# solox_a9 register map
File version: 1.0
Default CMSIS device
Registers are 32-bit, read-write, reset 0xFFFFFFFF unless marked. A register's access mark holds for its fields unless they carry their own. Offsets are from the block's base; lines under a group give offsets from that group; [hi:lo] are bit positions; {n}, {i} and the like mark numbered series; 'fields as' and 'values as' point back to an identical list; <NAME> marks a mode.

## Memory map
0x020C4000 CCM size 0x8C

## CCM
Base 0x020C4000
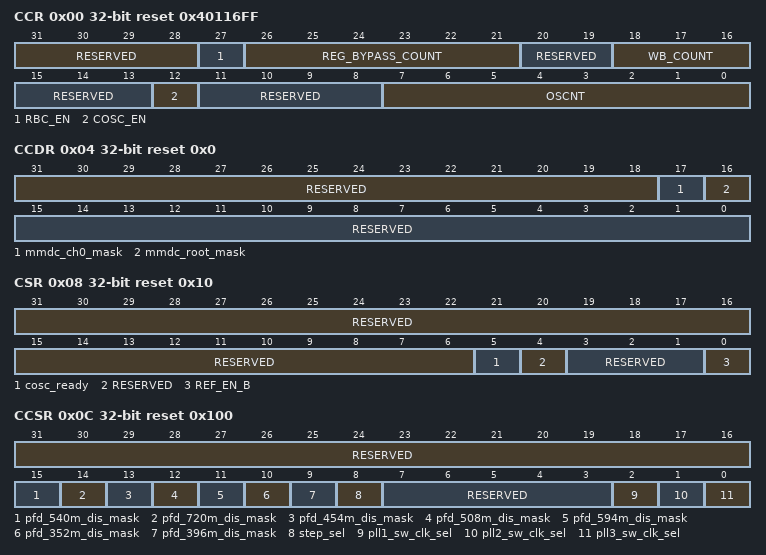
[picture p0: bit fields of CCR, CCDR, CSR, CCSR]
0x00 CCR reset 0x40116FF — CCM Control Register
  [31:28] RESERVED ro, [27] RBC_EN, [26:21] REG_BYPASS_COUNT, [20:19] RESERVED ro, [18:16] WB_COUNT, [15:13] RESERVED ro, [12] COSC_EN, [11:8] RESERVED ro, [7:0] OSCNT
0x04 CCDR reset 0x0 — CCM Control Divider Register
  [31:18] RESERVED ro, [17] mmdc_ch0_mask, [16] mmdc_root_mask, [15:0] RESERVED ro
0x08 CSR ro reset 0x10 — CCM Status Register
  [31:6] RESERVED, [5] cosc_ready, [4] RESERVED, [3:1] RESERVED, [0] REF_EN_B
0x0C CCSR reset 0x100 — CCM Clock Swither Register
  [31:16] RESERVED ro, [15] pfd_540m_dis_mask, [14] pfd_720m_dis_mask, [13] pfd_454m_dis_mask, [12] pfd_508m_dis_mask, [11] pfd_594m_dis_mask, [10] pfd_352m_dis_mask, [9] pfd_396m_dis_mask, [8] step_sel, [7:3] RESERVED ro, [2] pll1_sw_clk_sel, [1] pll2_sw_clk_sel, [0] pll3_sw_clk_sel
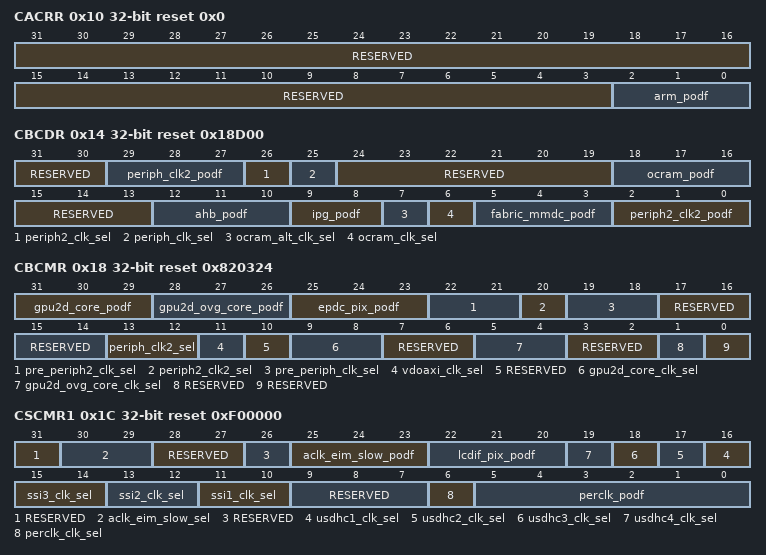
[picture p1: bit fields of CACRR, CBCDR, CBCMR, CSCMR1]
0x10 CACRR reset 0x0 — CCM Arm Clock Root Register
  [31:3] RESERVED ro, [2:0] arm_podf
0x14 CBCDR reset 0x18D00 — CCM Bus Clock Divider Register
  [31:30] RESERVED ro, [29:27] periph_clk2_podf, [26] periph2_clk_sel, [25] periph_clk_sel, [24:19] RESERVED ro, [18:16] ocram_podf, [15:13] RESERVED ro, [12:10] ahb_podf, [9:8] ipg_podf, [7] ocram_alt_clk_sel, [6] ocram_clk_sel, [5:3] fabric_mmdc_podf, [2:0] periph2_clk2_podf
0x18 CBCMR reset 0x820324 — CCM Bus Clock Multiplexer Register
  [31:29] gpu2d_core_podf, [28:26] gpu2d_ovg_core_podf, [25:23] epdc_pix_podf, [22:21] pre_periph2_clk_sel, [20] periph2_clk2_sel, [19:18] pre_periph_clk_sel, [17:16] RESERVED ro, [15:14] RESERVED ro, [13:12] periph_clk2_sel, [11] vdoaxi_clk_sel, [10] RESERVED ro, [9:8] gpu2d_core_clk_sel, [7:6] RESERVED ro, [5:4] gpu2d_ovg_core_clk_sel, [3:2] RESERVED ro, [1] RESERVED ro, [0] RESERVED ro
0x1C CSCMR1 reset 0xF00000 — CCM Serial Clock Multiplexer Register 1
  [31] RESERVED ro, [30:29] aclk_eim_slow_sel, [28:27] RESERVED ro, [26] RESERVED ro, [25:23] aclk_eim_slow_podf, [22:20] lcdif_pix_podf, [n+15] usdhc{n}_clk_sel (n=1..4), [15:14] ssi3_clk_sel, [13:12] ssi2_clk_sel, [11:10] ssi1_clk_sel, [9:7] RESERVED ro, [6] perclk_clk_sel, [5:0] perclk_podf
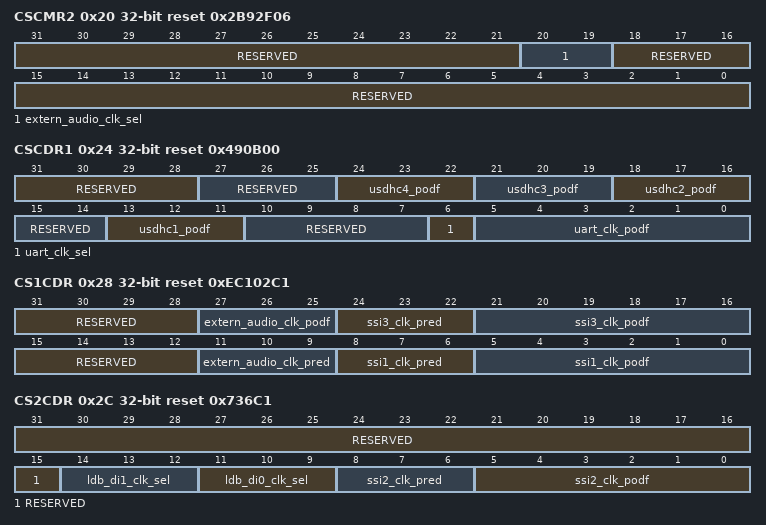
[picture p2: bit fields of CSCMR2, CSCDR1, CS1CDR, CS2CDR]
0x20 CSCMR2 reset 0x2B92F06 — CCM Serial Clock Multiplexer Register 2
  [31:21] RESERVED ro, [20:19] extern_audio_clk_sel, [18:0] RESERVED ro
0x24 CSCDR1 reset 0x490B00 — CCM Serial Clock Divider Register 1
  [31:28] RESERVED ro, [27:25] RESERVED ro, [24:22] usdhc4_podf, [21:19] usdhc3_podf, [18:16] usdhc2_podf, [15:14] RESERVED ro, [13:11] usdhc1_podf, [10:7] RESERVED ro, [6] uart_clk_sel, [5:0] uart_clk_podf
0x28 CS1CDR reset 0xEC102C1 — CCM SSI1 Clock Divider Register
  [31:28] RESERVED ro, [27:25] extern_audio_clk_podf, [24:22] ssi3_clk_pred, [21:16] ssi3_clk_podf, [15:12] RESERVED ro, [11:9] extern_audio_clk_pred, [8:6] ssi1_clk_pred, [5:0] ssi1_clk_podf
0x2C CS2CDR reset 0x736C1 — CCM SSI2 Clock Divider Register
  [31:15] RESERVED ro, [14:12] ldb_di1_clk_sel, [11:9] ldb_di0_clk_sel, [8:6] ssi2_clk_pred, [5:0] ssi2_clk_podf
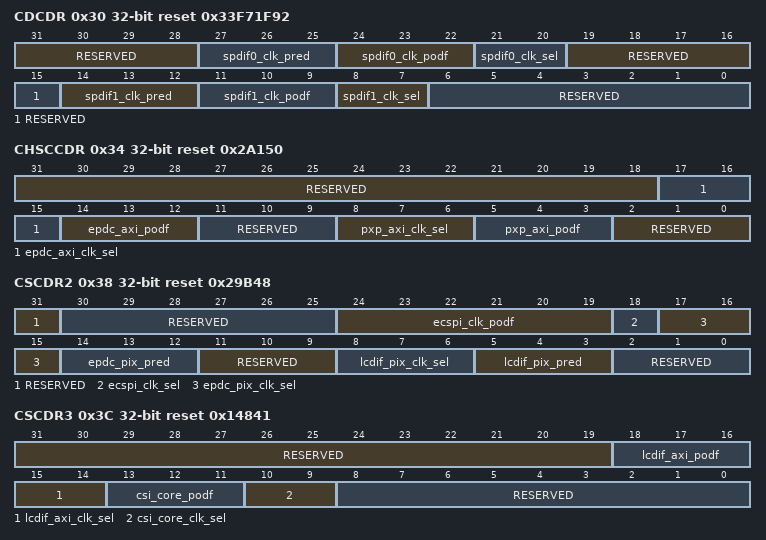
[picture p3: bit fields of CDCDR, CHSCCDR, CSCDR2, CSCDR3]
0x30 CDCDR reset 0x33F71F92 — CCM D1 Clock Divider Register
  [31:28] RESERVED ro, [27:25] spdif0_clk_pred, [24:22] spdif0_clk_podf, [21:20] spdif0_clk_sel, [19:16] RESERVED ro, [15] RESERVED ro, [14:12] spdif1_clk_pred, [11:9] spdif1_clk_podf, [8:7] spdif1_clk_sel, [6:0] RESERVED ro
0x34 CHSCCDR reset 0x2A150 — CCM HSC Clock Divider Register
  [31:18] RESERVED ro, [17:15] epdc_axi_clk_sel, [14:12] epdc_axi_podf, [11:9] RESERVED ro, [8:6] pxp_axi_clk_sel, [5:3] pxp_axi_podf, [2:0] RESERVED ro
0x38 CSCDR2 reset 0x29B48 — CCM Serial Clock Divider Register 2
  [31] RESERVED ro, [30:25] RESERVED ro, [24:19] ecspi_clk_podf, [18] ecspi_clk_sel, [17:15] epdc_pix_clk_sel, [14:12] epdc_pix_pred, [11:9] RESERVED ro, [8:6] lcdif_pix_clk_sel, [5:3] lcdif_pix_pred, [2:0] RESERVED ro
0x3C CSCDR3 reset 0x14841 — CCM Serial Clock Divider Register 3
  [31:19] RESERVED ro, [18:16] lcdif_axi_podf, [15:14] lcdif_axi_clk_sel, [13:11] csi_core_podf, [10:9] csi_core_clk_sel, [8:0] RESERVED ro
0x44 CWDR ro reset 0x0 — CCM Wakeup Detector Register
  [31:0] RESERVED
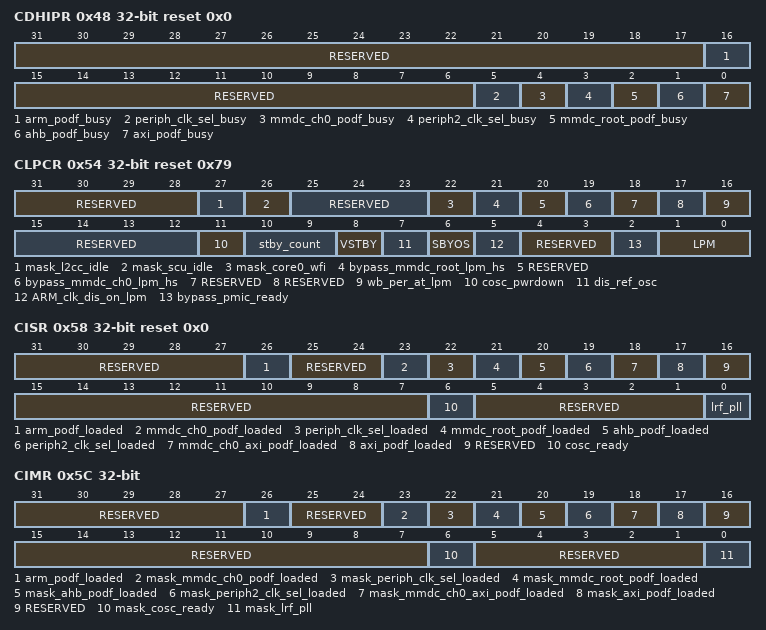
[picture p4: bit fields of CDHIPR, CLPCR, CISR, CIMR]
0x48 CDHIPR ro reset 0x0 — CCM Divider Handshake In-Process Register
  [31:17] RESERVED, [16] arm_podf_busy, [15:6] RESERVED, [5] periph_clk_sel_busy, [4] mmdc_ch0_podf_busy, [3] periph2_clk_sel_busy, [2] mmdc_root_podf_busy, [1] ahb_podf_busy, [0] axi_podf_busy
0x54 CLPCR reset 0x79 — CCM Low Power Control Register
  [31:28] RESERVED ro, [27] mask_l2cc_idle, [26] mask_scu_idle, [25:23] RESERVED ro, [22] mask_core0_wfi, [21] bypass_mmdc_root_lpm_hs, [20] RESERVED ro, [19] bypass_mmdc_ch0_lpm_hs, [18] RESERVED ro, [17] RESERVED ro, [16] wb_per_at_lpm, [15:12] RESERVED ro, [11] cosc_pwrdown, [10:9] stby_count, [8] VSTBY, [7] dis_ref_osc, [6] SBYOS, [5] ARM_clk_dis_on_lpm, [4:3] RESERVED ro, [2] bypass_pmic_ready, [1:0] LPM
0x58 CISR reset 0x0 — CCM Interrupt Status Register
  [31:27] RESERVED ro, [26] arm_podf_loaded, [25:24] RESERVED ro, [23] mmdc_ch0_podf_loaded, [22] periph_clk_sel_loaded, [21] mmdc_root_podf_loaded, [20] ahb_podf_loaded, [19] periph2_clk_sel_loaded, [18] mmdc_ch0_axi_podf_loaded ro, [17] axi_podf_loaded, [16:7] RESERVED ro, [6] cosc_ready, [5:1] RESERVED ro, [0] lrf_pll
0x5C CIMR — CCM Interrupt Mask Register
  [31:27] RESERVED ro, [26] arm_podf_loaded, [25:24] RESERVED ro, [23] mask_mmdc_ch0_podf_loaded, [22] mask_periph_clk_sel_loaded, [21] mask_mmdc_root_podf_loaded, [20] mask_ahb_podf_loaded, [19] mask_periph2_clk_sel_loaded, [18] mask_mmdc_ch0_axi_podf_loaded ro, [17] mask_axi_podf_loaded, [16:7] RESERVED ro, [6] mask_cosc_ready, [5:1] RESERVED ro, [0] mask_lrf_pll
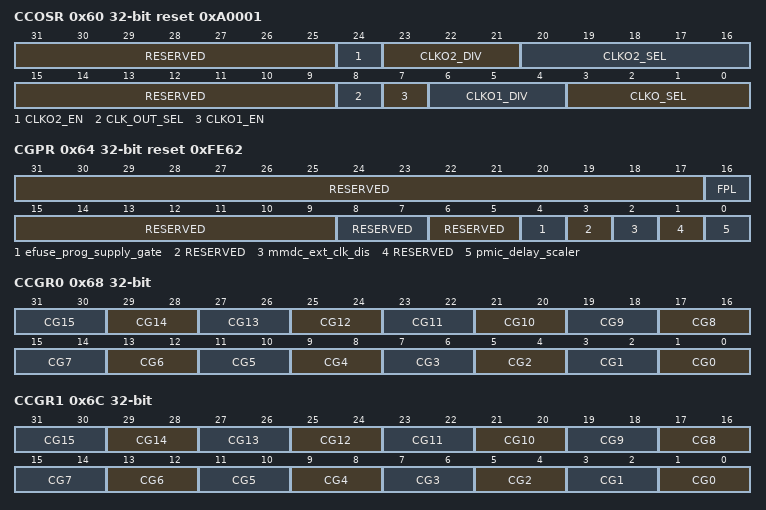
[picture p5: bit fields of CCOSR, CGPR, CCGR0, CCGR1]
0x60 CCOSR reset 0xA0001 — CCM Clock Output Source Register
  [31:25] RESERVED ro, [24] CLKO2_EN, [23:21] CLKO2_DIV, [20:16] CLKO2_SEL, [15:9] RESERVED ro, [8] CLK_OUT_SEL, [7] CLKO1_EN, [6:4] CLKO1_DIV, [3:0] CLKO_SEL
0x64 CGPR reset 0xFE62 — CCM General Purpose Register
  [31:17] RESERVED ro
  [16] FPL — Fast PLL enable.
  [15:9] RESERVED ro
  [8:7] RESERVED ro
  [6:5] RESERVED ro
  [4] efuse_prog_supply_gate
  [3] RESERVED ro
  [2] mmdc_ext_clk_dis
  [1] RESERVED wo
  [0] pmic_delay_scaler
0x68 CCGR0 — CCM Clock Gating Register 0
  [2n+1:2n] CG{n} (n=0..15)
0x6C CCGR1 — CCM Clock Gating Register 1
  [2n+1:2n] CG{n} (n=0..15)
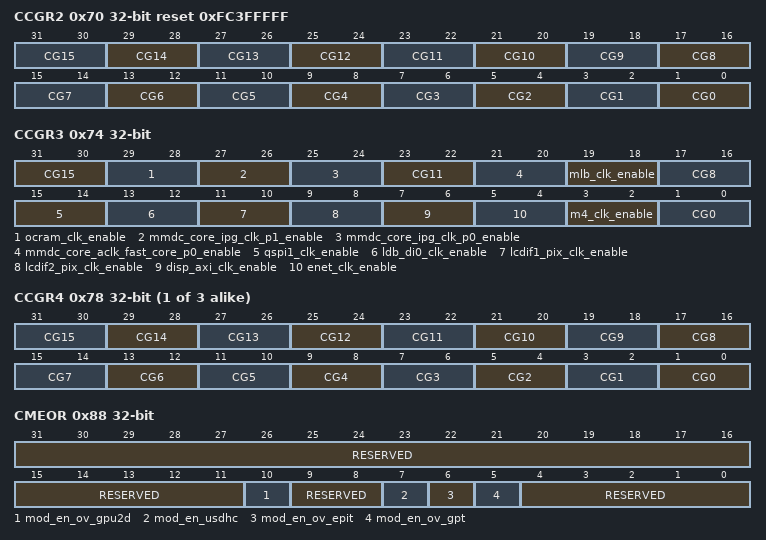
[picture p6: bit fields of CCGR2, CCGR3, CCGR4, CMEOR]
0x70 CCGR2 reset 0xFC3FFFFF — CCM Clock Gating Register 2
  [2n+1:2n] CG{n} (n=0..15)
0x74 CCGR3 — CCM Clock Gating Register 3
  [31:30] CG15 — Reserved
  [29:28] ocram_clk_enable — ocram clock
  [27:26] mmdc_core_ipg_clk_p1_enable — mmdc_core_ipg_clk_p1 clock
  [25:24] mmdc_core_ipg_clk_p0_enable — mmdc_core_ipg_clk_p0 clock
  [23:22] CG11 — Reserved
  [21:20] mmdc_core_aclk_fast_core_p0_enable — mmdc_core_aclk_fast_core_p0 clock
  [19:18] mlb_clk_enable — mlb clock
  [17:16] CG8 — Reserved
  [15:14] qspi1_clk_enable — qspi1 clock
  [13:12] ldb_di0_clk_enable — ldb_di0 clock
  [11:10] lcdif1_pix_clk_enable — lcdif1 pix clock
  [9:8] lcdif2_pix_clk_enable — lcdif2 pix clock
  [7:6] disp_axi_clk_enable — display axi clock
  [5:4] enet_clk_enable — enet clock
  [3:2] m4_clk_enable — m4 clock
  [1:0] CG0 — Reserved
{0x68+4i} CCGR{i} (i=4..6) — CCM Clock Gating Register {i}
  [2n+1:2n] CG{n} (n=0..15)
0x88 CMEOR — CCM Module Enable Overide Register
  [31:11] RESERVED ro, [10] mod_en_ov_gpu2d, [9:8] RESERVED ro, [7] mod_en_usdhc, [6] mod_en_ov_epit, [5] mod_en_ov_gpt, [4:0] RESERVED ro
